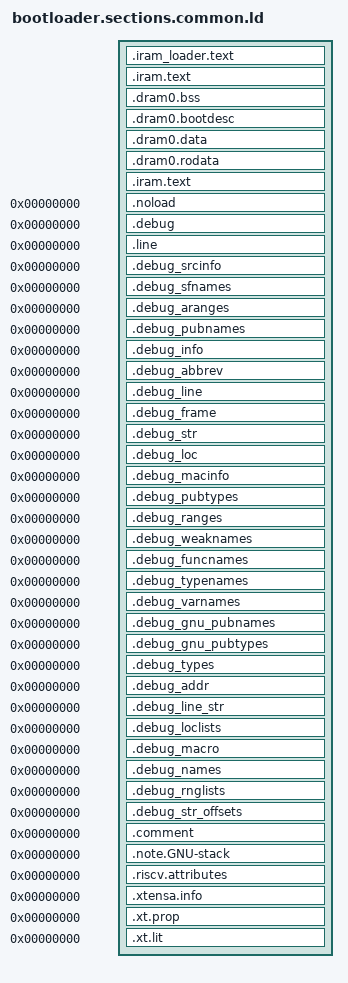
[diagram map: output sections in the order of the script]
/*
 * SPDX-FileCopyrightText: 2026 Espressif Systems (Shanghai) CO LTD
 *
 * SPDX-License-Identifier: Apache-2.0
 */

#include "sdkconfig.h"

/* Default entry point: */
ENTRY(call_start_cpu0);

SECTIONS
{

  .iram_loader.text :
  {
    . = ALIGN (16);
    _loader_text_start = ABSOLUTE(.);
    *(.stub .gnu.warning .gnu.linkonce.literal.* .gnu.linkonce.t.*.literal .gnu.linkonce.t.*)
    *(.iram1 .iram1.*) /* catch stray IRAM_ATTR */
    IRAM_LOADER_TEXT_INPUTS
    *(.fini.literal)
    *(.fini)
    *(.gnu.version)
    _loader_text_end = ABSOLUTE(.);
  } > iram_loader_seg

  .iram.text :
  {
    . = ALIGN (16);
    *(.entry.text)
    *(.init.literal)
    *(.init)
  } > iram_seg


  /* Shared RAM */
  .dram0.bss (NOLOAD) :
  {
    . = ALIGN (8);
    _dram_start = ABSOLUTE(.);
    _bss_start = ABSOLUTE(.);
    *(.dynsbss)
    *(.sbss)
    *(.sbss.*)
    *(.gnu.linkonce.sb.*)
    *(.scommon)
    *(.sbss2)
    *(.sbss2.*)
    *(.gnu.linkonce.sb2.*)
    *(.dynbss)
    *(.bss)
    *(.bss.*)
    *(.gnu.linkonce.b.*)
    *(COMMON)
    . = ALIGN (8);
    _bss_end = ABSOLUTE(.);
  } > dram_seg

  .dram0.bootdesc : ALIGN(0x10)
  {
    _data_start = ABSOLUTE(.);
    *(.data_bootloader_desc .data_bootloader_desc.*)               /* Should be the first.  Bootloader version info.        DO NOT PUT ANYTHING BEFORE IT! */
  } > dram_seg

  .dram0.data : ALIGN(0x10)
  {
    *(.dram1 .dram1.*) /* catch stray DRAM_ATTR */
    *(.data)
    *(.data.*)
    *(.gnu.linkonce.d.*)
    *(.data1)
    *(.sdata)
    *(.sdata.*)
    *(.gnu.linkonce.s.*)
    *(.gnu.linkonce.s2.*)
    *(.jcr)
    _data_end = ABSOLUTE(.);
  } > dram_seg

  .dram0.rodata :
  {
    _rodata_start = ABSOLUTE(.);
    *(.rodata)
    *(.rodata.*)
    *(.gnu.linkonce.r.*)
    *(.rodata1)
    *(.sdata2 .sdata2.* .srodata .srodata.*)
    __XT_EXCEPTION_TABLE_ = ABSOLUTE(.);
    *(.xt_except_table)
    *(.gcc_except_table)
    *(.gnu.linkonce.e.*)
    *(.gnu.version_r)
    *(.eh_frame_hdr)
    *(.eh_frame)
    . = (. + 3) & ~ 3;
    /* C++ constructor and destructor tables, properly ordered: */
    __init_array_start = ABSOLUTE(.);
    KEEP (*crtbegin.*(.ctors))
    KEEP (*(EXCLUDE_FILE (*crtend.*) .ctors))
    KEEP (*(SORT(.ctors.*)))
    KEEP (*(.ctors))
    __init_array_end = ABSOLUTE(.);
    KEEP (*crtbegin.*(.dtors))
    KEEP (*(EXCLUDE_FILE (*crtend.*) .dtors))
    KEEP (*(SORT(.dtors.*)))
    KEEP (*(.dtors))
    /*  C++ exception handlers table:  */
    __XT_EXCEPTION_DESCS_ = ABSOLUTE(.);
    *(.xt_except_desc)
    *(.gnu.linkonce.h.*)
    __XT_EXCEPTION_DESCS_END__ = ABSOLUTE(.);
    *(.xt_except_desc_end)
    *(.dynamic)
    *(.gnu.version_d)
    _rodata_end = ABSOLUTE(.);
    /* Literals are also RO data. */
    _lit4_start = ABSOLUTE(.);
    *(*.lit4)
    *(.lit4.*)
    *(.gnu.linkonce.lit4.*)
    _lit4_end = ABSOLUTE(.);
    . = ALIGN(4);
    _dram_end = ABSOLUTE(.);
  } > dram_seg

  .iram.text :
  {
    _stext = .;
    _text_start = ABSOLUTE(.);
    *(.literal .text .literal.* .text.* .stub .gnu.warning .gnu.linkonce.literal.* .gnu.linkonce.t.*.literal .gnu.linkonce.t.*)
    *(.iram .iram.*) /* catch stray IRAM_ATTR */
    *(.fini.literal)
    *(.fini)
    *(.gnu.version)

    /** CPU will try to prefetch up to 16 bytes of
      * of instructions. This means that any configuration (e.g. MMU, PMS) must allow
      * safe access to up to 16 bytes after the last real instruction, add
      * dummy bytes to ensure this
      */
    . += 16;

    _text_end = ABSOLUTE(.);
    _etext = .;
  } > iram_seg

  /**
   * Discarding .rela.* sections results in the following mapping:
   * .rela.text.* -> .text.*
   * .rela.data.* -> .data.*
   * And so forth...
   */
  /DISCARD/ : { *(.rela.*) }

  /**
   * This section is not included in the binary image; it is only present in the ELF file.
   * It is used to keep certain symbols in the ELF file.
   */
  .noload 0 (INFO) :
  {
    /* Reserve first 4 bytes as zero for vars pointed to NULL */
    . = 0;
    LONG(0);
    _noload_keep_in_elf_start = ABSOLUTE(.);
    KEEP(*(.noload_keep_in_elf .noload_keep_in_elf.*))
    _noload_keep_in_elf_end = ABSOLUTE(.);
  }

  /* DWARF 1 */
  .debug              0 : { *(.debug) }
  .line               0 : { *(.line) }

  /* GNU DWARF 1 extensions */
  .debug_srcinfo      0 : { *(.debug_srcinfo) }
  .debug_sfnames      0 : { *(.debug_sfnames) }

  /* DWARF 1.1 and DWARF 2 */
  .debug_aranges      0 : { *(.debug_aranges) }
  .debug_pubnames     0 : { *(.debug_pubnames) }

  /* DWARF 2 */
  .debug_info         0 : { *(.debug_info .gnu.linkonce.wi.*) }
  .debug_abbrev       0 : { *(.debug_abbrev) }
  .debug_line         0 : { *(.debug_line) }
  .debug_frame        0 : { *(.debug_frame) }
  .debug_str          0 : { *(.debug_str) }
  .debug_loc          0 : { *(.debug_loc) }
  .debug_macinfo      0 : { *(.debug_macinfo) }
  .debug_pubtypes     0 : { *(.debug_pubtypes) }

  /* DWARF 3 */
  .debug_ranges       0 : { *(.debug_ranges) }

  /* SGI/MIPS DWARF 2 extensions */
  .debug_weaknames    0 : { *(.debug_weaknames) }
  .debug_funcnames    0 : { *(.debug_funcnames) }
  .debug_typenames    0 : { *(.debug_typenames) }
  .debug_varnames     0 : { *(.debug_varnames) }

  /* GNU DWARF 2 extensions */
  .debug_gnu_pubnames 0 : { *(.debug_gnu_pubnames) }
  .debug_gnu_pubtypes 0 : { *(.debug_gnu_pubtypes) }

  /* DWARF 4 */
  .debug_types        0 : { *(.debug_types) }

  /* DWARF 5 */
  .debug_addr         0 : { *(.debug_addr) }
  .debug_line_str     0 : { *(.debug_line_str) }
  .debug_loclists     0 : { *(.debug_loclists) }
  .debug_macro        0 : { *(.debug_macro) }
  .debug_names        0 : { *(.debug_names) }
  .debug_rnglists     0 : { *(.debug_rnglists) }
  .debug_str_offsets  0 : { *(.debug_str_offsets) }

  /**
   * Miscellaneous sections
   */
  .comment            0 : { *(.comment) }
  .note.GNU-stack     0 : { *(.note.GNU-stack) }

  .riscv.attributes   0 : { *(.riscv.attributes) }

/**
 * .xt.prop and .xt.lit sections will be used by the debugger and disassembler
 * to get more information about raw data present in the code.
 * Indeed, it may be required to add some padding at some points in the code
 * in order to align a branch/jump destination on a particular bound.
 * Padding these instructions will generate null bytes that shall be
 * interpreted as data, and not code by the debugger or disassembler.
 * This section will only be present in the ELF file, not in the final binary
 * For more details, check GCC-212
 */
  .xtensa.info        0 : { *(.xtensa.info) }
  .xt.prop            0 : { *(.xt.prop .xt.prop.* .gnu.linkonce.prop.*) }
  .xt.lit             0 : { *(.xt.lit .xt.lit.* .gnu.linkonce.p.*) }

}
